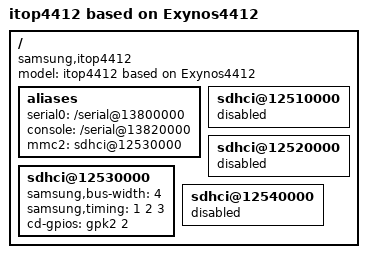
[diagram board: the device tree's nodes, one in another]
/*
 * Samsung's Exynos4412 based board device tree source
 *
 * Copyright (c) 2014 Samsung Electronics Co., Ltd.
 *		http://www.samsung.com
 *
 * SPDX-License-Identifier:	GPL-2.0+
 */

/dts-v1/;
#include "exynos4412.dtsi"

/ {
	model = "itop4412 based on Exynos4412";
	compatible = "samsung,itop4412", "samsung,exynos4412";

	aliases {
		serial0 = "/serial@13800000";
		console = "/serial@13820000";
		mmc2 = "sdhci@12530000";
	};

	sdhci@12510000 {
		status = "disabled";
	};

	sdhci@12520000 {
		status = "disabled";
	};

	sdhci@12530000 {
		samsung,bus-width = <4>;
		samsung,timing = <1 2 3>;
		cd-gpios = <&gpk2 2 0>;
	};

	sdhci@12540000 {
		status = "disabled";
	};
};
